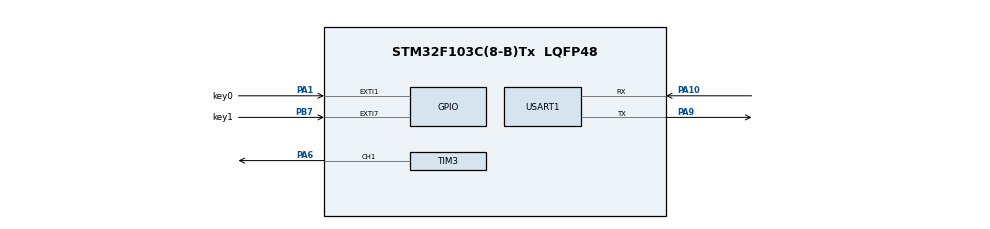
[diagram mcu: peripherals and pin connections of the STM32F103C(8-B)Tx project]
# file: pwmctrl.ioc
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Mcu.Family=STM32F1
Mcu.Name=STM32F103C(8-B)Tx
Mcu.Package=LQFP48
NVIC.EXTI1_IRQn=true\:0\:0\:false\:false\:true\:true\:true\:true
NVIC.EXTI9_5_IRQn=true\:0\:0\:false\:false\:true\:true\:true\:true
NVIC.PriorityGroup=NVIC_PRIORITYGROUP_4
PA1.GPIO_Label=key0
PA1.GPIO_PuPd=GPIO_PULLUP
PA1.Signal=GPXTI1
PA10.Mode=Asynchronous
PA10.Signal=USART1_RX
PA13.Mode=Serial_Wire
PA13.Signal=SYS_JTMS-SWDIO
PA14.Mode=Serial_Wire
PA14.Signal=SYS_JTCK-SWCLK
PA6.Signal=S_TIM3_CH1
PA9.Mode=Asynchronous
PA9.Signal=USART1_TX
PB7.GPIO_Label=key1
PB7.GPIO_PuPd=GPIO_PULLUP
PB7.Signal=GPXTI7
PD0-OSC_IN.Mode=HSE-External-Oscillator
PD0-OSC_IN.Signal=RCC_OSC_IN
PD1-OSC_OUT.Mode=HSE-External-Oscillator
PD1-OSC_OUT.Signal=RCC_OSC_OUT
ProjectManager.HeapSize=0x200
ProjectManager.StackSize=0x400
ProjectManager.TargetToolchain=MDK-ARM V5.32
RCC.APB1Freq_Value=8000000
RCC.APB2Freq_Value=8000000
SH.S_TIM3_CH1.0=TIM3_CH1,PWM Generation1 CH1
TIM3.AutoReloadPreload=TIM_AUTORELOAD_PRELOAD_ENABLE
TIM3.Channel-PWM\ Generation1\ CH1=TIM_CHANNEL_1
TIM3.OCPolarity_1=TIM_OCPOLARITY_LOW
TIM3.Period=1000-1
TIM3.Prescaler=7200-1
USART1.VirtualMode=VM_ASYNC
VP_TIM3_VS_ClockSourceINT.Mode=Internal
board=custom

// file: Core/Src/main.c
/* USER CODE BEGIN Header */
/**
  ******************************************************************************
  * @file           : main.c
  * @brief          : Main program body
  ******************************************************************************
  * @attention
  *
  * Copyright (c) 2024 STMicroelectronics.
  * All rights reserved.
  *
  * This software is licensed under terms that can be found in the LICENSE file
  * in the root directory of this software component.
  * If no LICENSE file comes with this software, it is provided AS-IS.
  *
  ******************************************************************************
  */
/* USER CODE END Header */
#include "main.h"
#include "tim.h"
#include "usart.h"
#include "gpio.h"

void SystemClock_Config(void);

/* USER CODE BEGIN 0 */
uint16_t duty=0;
/* USER CODE END 0 */

int main(void)
{

  /* MCU Configuration--------------------------------------------------------*/

  /* Reset of all peripherals, Initializes the Flash interface and the Systick. */
  HAL_Init();

  /* Configure the system clock */
  SystemClock_Config();

  /* Initialize all configured peripherals */
  MX_GPIO_Init();
  MX_TIM3_Init();
  MX_USART1_UART_Init();

  /* Infinite loop */
  /* USER CODE BEGIN WHILE */
  while (1)
  {
	if(  duty>1000){
		duty=0;
	}
	if(keynum==1){
		keynum=0;
		duty+=100;

	}else if(keynum==2){
		keynum=0;
		duty-=100;

	}
	setduty(duty);
	printf("duty:%d\n",duty);
    /* USER CODE END WHILE */

  }
}

void SystemClock_Config(void)
{
  RCC_OscInitTypeDef RCC_OscInitStruct = {0};
  RCC_ClkInitTypeDef RCC_ClkInitStruct = {0};

  /** Initializes the RCC Oscillators according to the specified parameters
  * in the RCC_OscInitTypeDef structure.
  */
  RCC_OscInitStruct.OscillatorType = RCC_OSCILLATORTYPE_HSI;
  RCC_OscInitStruct.HSIState = RCC_HSI_ON;
  RCC_OscInitStruct.HSICalibrationValue = RCC_HSICALIBRATION_DEFAULT;
  RCC_OscInitStruct.PLL.PLLState = RCC_PLL_NONE;
  if (HAL_RCC_OscConfig(&RCC_OscInitStruct) != HAL_OK)
  {
    Error_Handler();
  }

  /** Initializes the CPU, AHB and APB buses clocks
  */
  RCC_ClkInitStruct.ClockType = RCC_CLOCKTYPE_HCLK|RCC_CLOCKTYPE_SYSCLK
                              |RCC_CLOCKTYPE_PCLK1|RCC_CLOCKTYPE_PCLK2;
  RCC_ClkInitStruct.SYSCLKSource = RCC_SYSCLKSOURCE_HSI;
  RCC_ClkInitStruct.AHBCLKDivider = RCC_SYSCLK_DIV1;
  RCC_ClkInitStruct.APB1CLKDivider = RCC_HCLK_DIV1;
  RCC_ClkInitStruct.APB2CLKDivider = RCC_HCLK_DIV1;

  if (HAL_RCC_ClockConfig(&RCC_ClkInitStruct, FLASH_LATENCY_0) != HAL_OK)
  {
    Error_Handler();
  }
}

void Error_Handler(void)
{
  __disable_irq();
  while (1)
  {
  }
}
